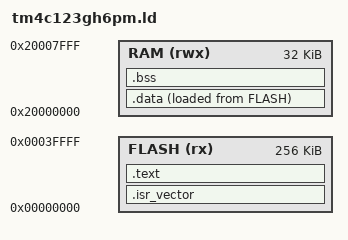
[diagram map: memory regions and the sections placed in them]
/*
 * Linker script for TM4C123GH6PM
 * Memory layout:
 *   Flash: 0x00000000 - 0x0003FFFF (256KB)
 *   RAM:   0x20000000 - 0x20007FFF (32KB)
 */

MEMORY
{
    FLASH (rx) : ORIGIN = 0x00000000, LENGTH = 256K
    RAM (rwx)  : ORIGIN = 0x20000000, LENGTH = 32K
}

_estack = 0x20008000;  /* Top of stack */

SECTIONS
{
    .isr_vector : {
        KEEP(*(.isr_vector))
    } > FLASH

    .text : {
        *(.text*)
        *(.rodata*)
        _etext = .;
    } > FLASH

    _sidata = LOADADDR(.data);
    
    .data : {
        _sdata = .;
        *(.data*)
        _edata = .;
    } > RAM AT > FLASH

    .bss : {
        _sbss = .;
        *(.bss*)
        *(COMMON)
        _ebss = .;
    } > RAM
}
